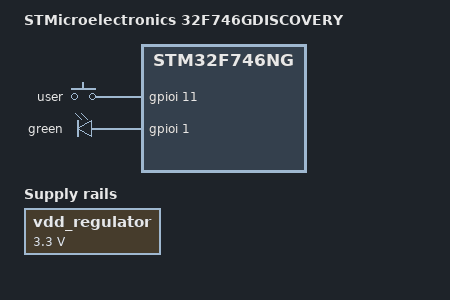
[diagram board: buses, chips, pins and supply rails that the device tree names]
/**
 * \file
 * \brief Devicetree for 32F746GDISCOVERY
 *
 * \author Copyright (C) 2017 Kamil Szczygiel http://www.distortec.com http://www.freddiechopin.info
 *
 * \par License
 * This Source Code Form is subject to the terms of the Mozilla Public License, v. 2.0. If a copy of the MPL was not
 * distributed with this file, You can obtain one at http://mozilla.org/MPL/2.0/.
 */

/dts-v1/;

#include "STM32F746NG.dtsi"

/ {
	compatible = "ST,32F746GDISCOVERY", "ST,STM32F746NG";
	model = "STMicroelectronics 32F746GDISCOVERY";

	buttons {
		compatible = "gpio-keys";
		status = "okay";

		b1 {
			gpios = <&gpioi 11 0>;
			label = "user";
			status = "okay";
		};
	};

	leds {
		compatible = "gpio-leds";
		status = "okay";

		ld1 {
			gpios = <&gpioi 1 0>;
			label = "green";
			status = "okay";
		};
	};

	regulators {
		#address-cells = <1>;
		#size-cells = <0>;

		vdd_regulator: regulator@0 {
			compatible = "regulator-fixed";
			reg = <0>;
			regulator-name = "VDD";
			regulator-min-microvolt = <3300000>;
			regulator-max-microvolt = <3300000>;
			regulator-always-on;
		};
	};
};

&clock_hse {
	ST,STM32-HSE-bypass;
	clock-frequency = <25000000>;
};

&gpioi {
	status = "okay";
};
